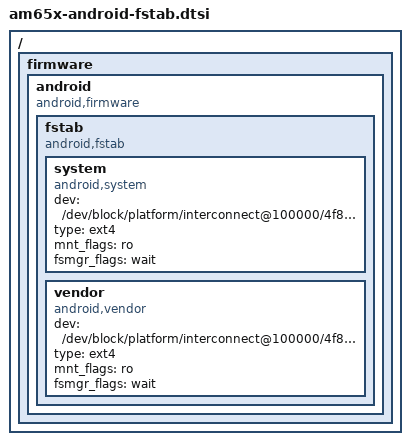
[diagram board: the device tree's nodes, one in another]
// SPDX-License-Identifier: GPL-2.0
/*
 * Copyright (C) 2018 Texas Instruments Incorporated - http://www.ti.com/
 */

/ {
	firmware {
		android {
			compatible = "android,firmware";
			fstab {
				compatible = "android,fstab";
				system {
					compatible = "android,system";
					dev = "/dev/block/platform/interconnect@100000/4f80000.sdhci/by-name/system";
					type = "ext4";
					mnt_flags = "ro";
					fsmgr_flags = "wait";
				};
				vendor {
					compatible = "android,vendor";
					dev = "/dev/block/platform/interconnect@100000/4f80000.sdhci/by-name/vendor";
					type = "ext4";
					mnt_flags = "ro";
					fsmgr_flags = "wait";
				};
			};
		};
	};
};
